VERSION ""

NS_ :

BS_:

BU_:

BO_ 1024 Dashboard_msg: 1 Vector__XXX
 SG_ lamp_status : 0|1@1+ (1,0) [0|1] "" Vector__XXX
 SG_ Buzzar_status : 1|1@1+ (1,0) [0|1] "" Vector__XXX

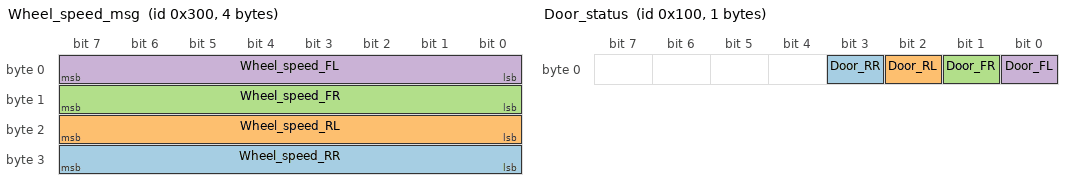
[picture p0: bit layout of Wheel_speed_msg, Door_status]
BO_ 768 Wheel_speed_msg: 4 Vector__XXX
 SG_ Wheel_speed_RR : 24|8@1+ (1,0) [0|255] "km/h" Vector__XXX
 SG_ Wheel_speed_RL : 16|8@1+ (1,0) [0|255] "km/h" Vector__XXX
 SG_ Wheel_speed_FR : 8|8@1+ (1,0) [0|255] "km/h" Vector__XXX
 SG_ Wheel_speed_FL : 0|8@1+ (1,0) [0|255] "km/h" Vector__XXX

BO_ 512 Seatbelt_status: 1 Vector__XXX
 SG_ seat_belt_status : 0|1@1+ (1,0) [0|1] "" Vector__XXX

BO_ 256 Door_status: 1 Vector__XXX
 SG_ Door_RR : 3|1@1+ (1,0) [0|1] "" Vector__XXX
 SG_ Door_RL : 2|1@1+ (1,0) [0|1] "" Vector__XXX
 SG_ Door_FR : 1|1@1+ (1,0) [0|1] "" Vector__XXX
 SG_ Door_FL : 0|1@1+ (1,0) [0|1] "" Vector__XXX

CM_ BO_ 256 "door status of the car";
